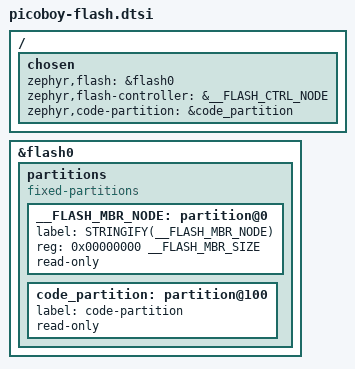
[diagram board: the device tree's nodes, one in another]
/*
 * Copyright (c) 2023-2025 TiaC Systems
 * SPDX-License-Identifier: Apache-2.0
 */

#define __STRINGIFY(x) #x
#define STRINGIFY(s) __STRINGIFY(s)

/ {
	chosen {
		zephyr,flash = &flash0;
		zephyr,flash-controller = &__FLASH_CTRL_NODE;
		zephyr,code-partition = &code_partition;
	};
};

&flash0 {
	partitions {
		compatible = "fixed-partitions";
		#address-cells = <1>;
		#size-cells = <1>;

		/* Reserved memory for the RP2040 second stage bootloader. */
		__FLASH_MBR_NODE: partition@0 {
			label = STRINGIFY(__FLASH_MBR_NODE);
			reg = <0x00000000 __FLASH_MBR_SIZE>;
			read-only;
		};

		/* Rest for code */
		code_partition: partition@100 {
			label = "code-partition";
			read-only;
		};
	};
};

#undef STRINGIFY
#undef __STRINGIFY
